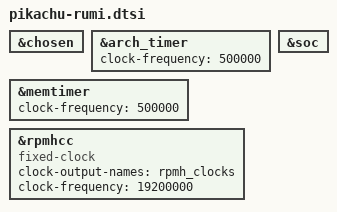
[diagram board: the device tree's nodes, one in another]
// SPDX-License-Identifier: BSD-3-Clause
/*
 * Copyright (c) Qualcomm Technologies, Inc. and/or its subsidiaries.
 */

&chosen {
};

&arch_timer {
	clock-frequency = <500000>;
};

&memtimer {
	clock-frequency = <500000>;
};

&soc {
};

&rpmhcc {
	compatible = "fixed-clock";
	clock-output-names = "rpmh_clocks";
	clock-frequency = <19200000>;
};
